# nrf54h20_enga_application register map
Vendor: Nordic Semiconductor; Series: nRF54h; File version: 1
CPU: CM33 r0p4, little endian, MPU, FPU, 3 interrupt priority bits, 480 interrupts, 4 SAU regions
Registers are 32-bit, read-write, reset 0x0 unless marked. A register's access mark holds for its fields unless they carry their own. Offsets are from the block's base; [hi:lo] are bit positions; lines under a group give offsets from that group; {n}, {i} and the like mark numbered series; 'fields as' and 'values as' point back to an identical list.

## GLOBAL_USBHSCORE0_NS (part 2 of 2) — USBHSCORE 0
Base 0x2F700000
Same registers: GLOBAL_USBHSCORE0_S 0x2F700000 (alternate view of GLOBAL_USBHSCORE0_NS)
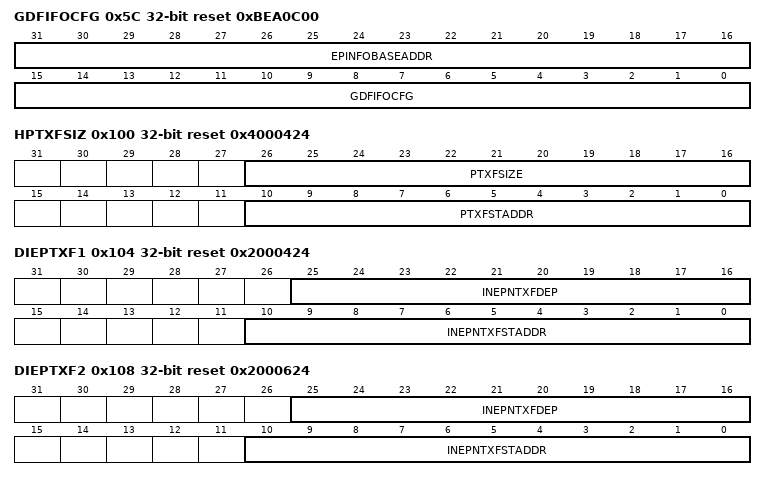
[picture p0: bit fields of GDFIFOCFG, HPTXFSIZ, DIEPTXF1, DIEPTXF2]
0x5C GDFIFOCFG reset 0xBEA0C00 — Global DFIFO Configuration Register
  [31:16] EPINFOBASEADDR, [15:0] GDFIFOCFG
0x68 GINTMSK2 — Interrupt Mask Register 2
0x6C GINTSTS2 — Interrupt Register 2
0x100 HPTXFSIZ reset 0x4000424 — Host Periodic Transmit FIFO Size Register
  [26:16] PTXFSIZE — Host Periodic TxFIFO Depth (PTxFSize)
  [10:0] PTXFSTADDR — Host Periodic TxFIFO Start Address (PTxFStAddr)
0x104 DIEPTXF1 reset 0x2000424 — Device IN Endpoint Transmit FIFO Size Register 1
  [25:16] INEPNTXFDEP — IN Endpoint TxFIFO Depth (INEPnTxFDep)
  [10:0] INEPNTXFSTADDR — IN Endpoint FIFOn Transmit RAM Start Address (INEPnTxFStAddr)
0x108 DIEPTXF2 reset 0x2000624 — Device IN Endpoint Transmit FIFO Size Register 2
  fields as DIEPTXF1
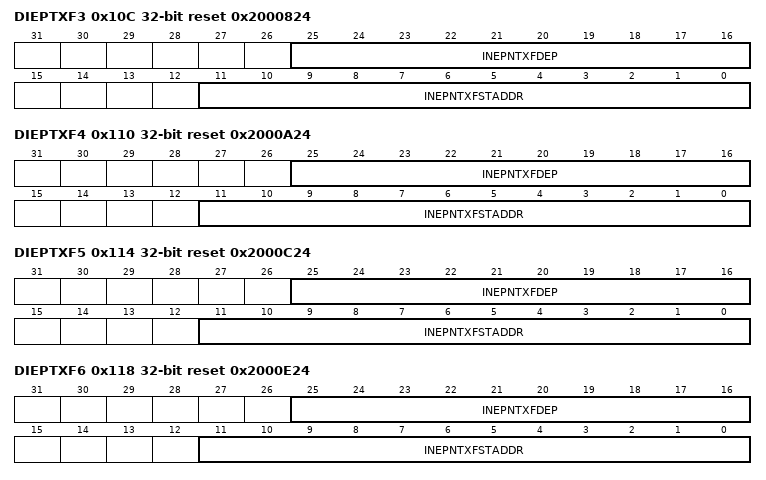
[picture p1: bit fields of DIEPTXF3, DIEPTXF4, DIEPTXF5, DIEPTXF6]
0x10C DIEPTXF3 reset 0x2000824 — Device IN Endpoint Transmit FIFO Size Register 3
  [25:16] INEPNTXFDEP — IN Endpoint TxFIFO Depth (INEPnTxFDep)
  [11:0] INEPNTXFSTADDR — IN Endpoint FIFOn Transmit RAM Start Address (INEPnTxFStAddr)
0x110 DIEPTXF4 reset 0x2000A24 — Device IN Endpoint Transmit FIFO Size Register 4
  fields as DIEPTXF3
0x114 DIEPTXF5 reset 0x2000C24 — Device IN Endpoint Transmit FIFO Size Register 5
  fields as DIEPTXF3
0x118 DIEPTXF6 reset 0x2000E24 — Device IN Endpoint Transmit FIFO Size Register 6
  fields as DIEPTXF3
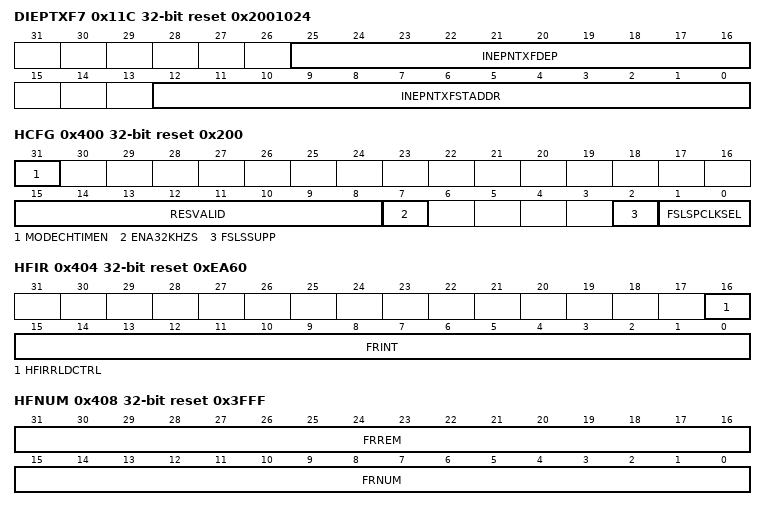
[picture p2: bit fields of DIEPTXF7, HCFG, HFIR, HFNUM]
0x11C DIEPTXF7 reset 0x2001024 — Device IN Endpoint Transmit FIFO Size Register 7
  [25:16] INEPNTXFDEP — IN Endpoint TxFIFO Depth (INEPnTxFDep)
  [12:0] INEPNTXFSTADDR — IN Endpoint FIFOn Transmit RAM Start Address (INEPnTxFStAddr)
0x400 HCFG reset 0x200 — Host Configuration Register
  [31] MODECHTIMEN — Mode Change Ready Timer Enable (ModeChTimEn)
    0=ENABLED (Unspecified); 1=DISABLED (Unspecified)
  [15:8] RESVALID — Resume Validation Period (ResValid)
  [7] ENA32KHZS — Enable 32 KHz Suspend mode (Ena32KHzS)
    0=DISABLED (Unspecified); 1=ENABLED (Unspecified)
  [2] FSLSSUPP — FS- and LS-Only Support (FSLSSupp)
    0=HSFSLS (Unspecified); 1=FSLS (Unspecified)
  [1:0] FSLSPCLKSEL — FS/LS PHY Clock Select (FSLSPclkSel)
    0=CLK3060 (Unspecified); 1=CLK48 (Unspecified); 2=CLK6 (Unspecified)
0x404 HFIR reset 0xEA60 — Host Frame Interval Register
  [16] HFIRRLDCTRL — Reload Control (HFIRRldCtrl)
    0=DISABLED (Unspecified); 1=ENABLED (Unspecified)
  [15:0] FRINT — Frame Interval (FrInt)
0x408 HFNUM reset 0x3FFF — Host Frame Number/Frame Time Remaining Register
  [31:16] FRREM ro — Frame Time Remaining (FrRem)
  [15:0] FRNUM ro — Frame Number (FrNum)
    0=INACTIVE (Unspecified); 1=ACTIVE (Unspecified)
0x414 HAINT — Host All Channels Interrupt Register
  [15:0] HAINT ro — Channel Interrupt for channel no.
    0=INACTIVE (Unspecified); 1=ACTIVE (Unspecified)
0x418 HAINTMSK — Host All Channels Interrupt Mask Register
  [15:0] HAINTMSK — Channel Interrupt Mask (HAINTMsk)
    0=UNMASK (Unspecified); 1=MASK (Unspecified)
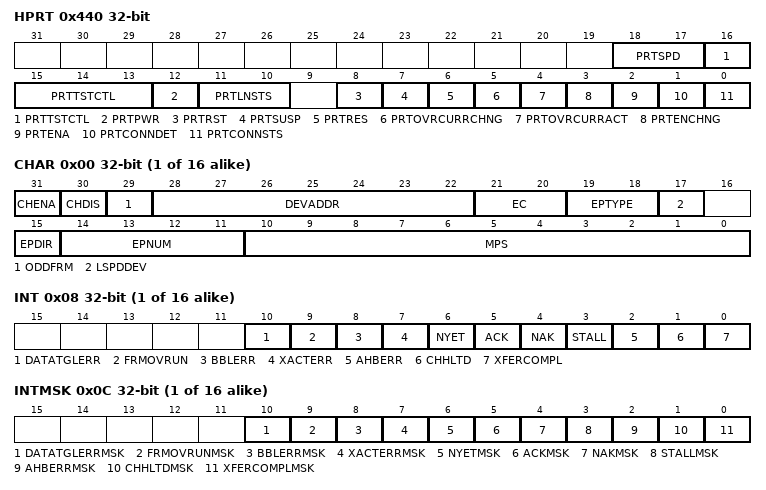
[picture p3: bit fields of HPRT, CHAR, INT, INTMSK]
0x440 HPRT — Host Port Control and Status Register
  [18:17] PRTSPD ro — Port Speed (PrtSpd)
    0=HIGHSPD (Unspecified); 1=FULLSPD (Unspecified); 2=LOWSPD (Unspecified)
  [16:13] PRTTSTCTL — Port Test Control (PrtTstCtl)
    0=DISABLED (Unspecified); 1=TESTJ (Unspecified); 2=TESTK (Unspecified); 3=TESTSN (Unspecified); 4=TESTPM (Unspecified); 5=TESTFENB (Unspecified)
  [12] PRTPWR — Port Power (PrtPwr)
    0=OFF (Unspecified); 1=ON (Unspecified)
  [11:10] PRTLNSTS ro — Port Line Status (PrtLnSts)
    1=PLUSD (Unspecified); 2=MINUSD (Unspecified)
  [8] PRTRST — Port Reset (PrtRst)
    0=DISABLED (Unspecified); 1=ENABLED (Unspecified)
  [7] PRTSUSP — Port Suspend (PrtSusp)
    0=INACTIVE (Unspecified); 1=ACTIVE (Unspecified)
  [6] PRTRES — Port Resume (PrtRes)
    0=NORESUME (Unspecified); 1=RESUME (Unspecified)
  [5] PRTOVRCURRCHNG — Port Overcurrent Change (PrtOvrCurrChng)
    0=INACTIVE (Unspecified); 1=ACTIVE (Unspecified)
  [4] PRTOVRCURRACT ro — Port Overcurrent Active (PrtOvrCurrAct)
    0=INACTIVE (Unspecified); 1=ACTIVE (Unspecified)
  [3] PRTENCHNG — Port Enable/Disable Change (PrtEnChng)
    0=INACTIVE (Unspecified); 1=ACTIVE (Unspecified)
  [2] PRTENA — Port Enable (PrtEna)
    0=DISABLED (Unspecified); 1=ENABLED (Unspecified)
  [1] PRTCONNDET — Port Connect Detected (PrtConnDet)
    0=INACTIVE (Unspecified); 1=ACTIVE (Unspecified)
  [0] PRTCONNSTS ro — Port Connect Status (PrtConnSts)
    0=NOTATTACHED (Unspecified); 1=ATTACHED (Unspecified)
{0x500+0x20*i} HC[{i}] (i=0..15) group — Unspecified
  0x00 CHAR — Description cluster: Host Channel n Characteristics Register
    [31] CHENA — Channel Enable (ChEna)
      0=DISABLED (Unspecified); 1=ENABLED (Unspecified)
    [30] CHDIS — Channel Disable (ChDis)
      0=INACTIVE (Unspecified); 1=ACTIVE (Unspecified)
    [29] ODDFRM — Odd Frame (OddFrm)
      0=EFRAME (Unspecified); 1=OFRAME (Unspecified)
    [28:22] DEVADDR — Device Address (DevAddr)
    [21:20] EC — Multi Count (MC) / Error Count (EC)
      1=TRANSONE (Unspecified); 2=TRANSTWO (Unspecified); 3=TRANSTHREE (Unspecified)
    [19:18] EPTYPE — Endpoint Type (EPType)
      0=CTRL (Unspecified); 1=ISOC (Unspecified); 2=BULK (Unspecified); 3=INTERR (Unspecified)
    [17] LSPDDEV — Low-Speed Device (LSpdDev)
      0=DISABLED (Unspecified); 1=ENABLED (Unspecified)
    [15] EPDIR — Endpoint Direction (EPDir)
      0=OUT (Unspecified); 1=IN (Unspecified)
    [14:11] EPNUM — Endpoint Number (EPNum)
      {v}=ENDPT{v} (Unspecified) (v=0..15)
    [10:0] MPS — Maximum Packet Size (MPS)
  0x08 INT — Description cluster: Host Channel n Interrupt Register
    [all] fields
      0=INACTIVE (Unspecified); 1=ACTIVE (Unspecified)
    [10] DATATGLERR — Data Toggle Error (DataTglErr).This bit can be set only by the core and the application should write 1 to clear
    [9] FRMOVRUN — Frame Overrun (FrmOvrun).
    [8] BBLERR — Babble Error (BblErr)
    [7] XACTERR — Transaction Error (XactErr)
    [6] NYET — NYET Response Received Interrupt (NYET)
    [5] ACK — ACK Response Received/Transmitted Interrupt (ACK)
    [4] NAK — NAK Response Received Interrupt (NAK)
    [3] STALL — STALL Response Received Interrupt (STALL)
    [2] AHBERR — AHB Error (AHBErr)
    [1] CHHLTD — Channel Halted (ChHltd)
    [0] XFERCOMPL — Transfer Completed (XferCompl)
  0x0C INTMSK — Description cluster: Host Channel n Interrupt Mask Register
    [all] fields
      0=MASK (Unspecified); 1=NOMASK (Unspecified)
    [10] DATATGLERRMSK — Data Toggle Error Mask (DataTglErrMsk)
    [9] FRMOVRUNMSK — Frame Overrun Mask (FrmOvrunMsk)
    [8] BBLERRMSK — Babble Error Mask (BblErrMsk)
    [7] XACTERRMSK — Transaction Error Mask (XactErrMsk)
    [6] NYETMSK — NYET Response Received Interrupt Mask (NyetMsk)
    [5] ACKMSK — ACK Response Received/Transmitted Interrupt Mask (AckMsk)
    [4] NAKMSK — NAK Response Received Interrupt Mask (NakMsk)
    [3] STALLMSK — STALL Response Received Interrupt Mask (StallMsk)
    [2] AHBERRMSK — AHB Error Mask (AHBErrMsk)
    [1] CHHLTDMSK — Channel Halted Mask (ChHltdMsk)
    [0] XFERCOMPLMSK — Transfer Completed Mask (XferComplMsk)
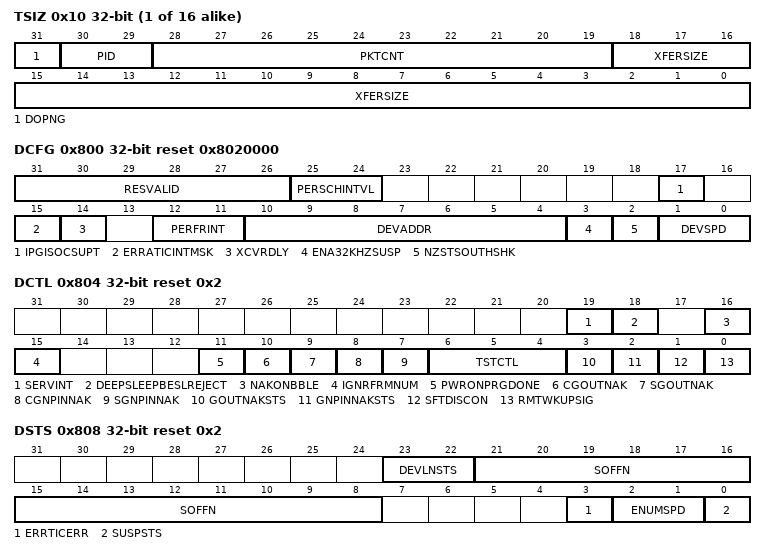
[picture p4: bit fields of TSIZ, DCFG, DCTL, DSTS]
  0x10 TSIZ — Description cluster: Host Channel n Transfer Size Register
    [31] DOPNG — Do Ping (DoPng)
      0=NOPING (Unspecified); 1=PING (Unspecified)
    [30:29] PID — PID (Pid)
      0=DATA0 (Unspecified); 1=DATA2 (Unspecified); 2=DATA1 (Unspecified); 3=MDATA (Unspecified)
    [28:19] PKTCNT — Packet Count (PktCnt)
    [18:0] XFERSIZE — Transfer Size (XferSize)
  0x14 DMA — Description cluster: Host Channel n DMA Address Register
    [31:0] DMAADDR — In Buffer DMA Mode:
0x800 DCFG reset 0x8020000 — Device Configuration Register
  [31:26] RESVALID — Resume Validation Period (ResValid)
  [25:24] PERSCHINTVL — Periodic Scheduling Interval (PerSchIntvl)
    0=MF25 (Unspecified); 1=MF50 (Unspecified); 2=MF75 (Unspecified)
  [17] IPGISOCSUPT — Worst-Case Inter-Packet Gap ISOC OUT Support (ipgisocSupt)
    0=DISABLED (Unspecified); 1=ENABLED (Unspecified)
  [15] ERRATICINTMSK — Erratic Error Interrupt Mask
    0=NOMASK (Unspecified); 1=MASK (Unspecified)
  [14] XCVRDLY
    0=DISABLE (Unspecified); 1=ENABLE (Unspecified)
  [12:11] PERFRINT — Periodic Frame Interval (PerFrInt)
    0=EOPF80 (Unspecified); 1=EOPF85 (Unspecified); 2=EOPF90 (Unspecified); 3=EOPF95 (Unspecified)
  [10:4] DEVADDR — Device Address (DevAddr)
  [3] ENA32KHZSUSP — Enable 32 KHz Suspend mode (Ena32KHzSusp)
    0=DISABLED (Unspecified); 1=ENABLED (Unspecified)
  [2] NZSTSOUTHSHK — Non-Zero-Length Status OUT Handshake (NZStsOUTHShk)
    0=SENDOUT (Unspecified); 1=SENDSTALL (Unspecified)
  [1:0] DEVSPD — Device Speed (DevSpd)
    0=USBHS20 (Unspecified); 1=USBFS20 (Unspecified); 2=USBLS116 (Unspecified); 3=USBFS1148 (Unspecified)
0x804 DCTL reset 0x2 — Device Control Register
  [19] SERVINT — Service Interval based scheduling for Isochronous IN Endpoints
    0=DISABLED (Unspecified); 1=ENABLED (Unspecified)
  [18] DEEPSLEEPBESLREJECT
    0=DISABLED (Unspecified); 1=ENABLED (Unspecified)
  [16] NAKONBBLE — NAK on Babble Error (NakOnBble)
    0=DISABLED (Unspecified); 1=ENABLED (Unspecified)
  [15] IGNRFRMNUM — Ignore Frame Number Feature for Isochronous Endpoints (IgnrFrmNum)
    0=DISABLED (Unspecified); 1=ENABLED (Unspecified)
  [11] PWRONPRGDONE — Power-On Programming Done (PWROnPrgDone)
    0=NOTDONE (Unspecified); 1=DONE (Unspecified)
  [10] CGOUTNAK wo — Clear Global OUT NAK (CGOUTNak)
    0=DISABLED (Unspecified); 1=ENABLED (Unspecified)
  [9] SGOUTNAK wo — Set Global OUT NAK (SGOUTNak)
    0=DISABLED (Unspecified); 1=ENABLED (Unspecified)
  [8] CGNPINNAK wo — Clear Global Non-periodic IN NAK (CGNPInNak)
    0=DISABLE (Unspecified); 1=ENABLE (Unspecified)
  [7] SGNPINNAK wo — Set Global Non-periodic IN NAK (SGNPInNak)
    0=DISABLE (Unspecified); 1=ENABLE (Unspecified)
  [6:4] TSTCTL — Test Control (TstCtl)
    0=DISABLED (Unspecified); 1=TESTJ (Unspecified); 2=TESTK (Unspecified); 3=TESTSN (Unspecified); 4=TESTPM (Unspecified); 5=TESTFE (Unspecified)
  [3] GOUTNAKSTS ro — Global OUT NAK Status (GOUTNakSts)
    0=INACTIVE (Unspecified); 1=ACTIVE (Unspecified)
  [2] GNPINNAKSTS ro — Global Non-periodic IN NAK Status (GNPINNakSts)
    0=INACTIVE (Unspecified); 1=ACTIVE (Unspecified)
  [1] SFTDISCON — Soft Disconnect (SftDiscon)
    0=NODISCONNECT (Unspecified); 1=DISCONNECT (Unspecified)
  [0] RMTWKUPSIG — Remote Wakeup Signaling (RmtWkUpSig)
    0=DISABLEDRMWKUP (Unspecified); 1=ENABLERMWKUP (Unspecified)
0x808 DSTS reset 0x2 — Device Status Register
  [23:22] DEVLNSTS ro — Device Line Status (DevLnSts)
  [21:8] SOFFN ro — Frame or Microframe Number of the Received SOF (SOFFN)
  [3] ERRTICERR ro — Erratic Error (ErrticErr)
    0=INACTIVE (Unspecified); 1=ACTIVE (Unspecified)
  [2:1] ENUMSPD ro — Enumerated Speed (EnumSpd)
    0=HS3060 (Unspecified); 1=FS3060 (Unspecified); 2=LS6 (Unspecified); 3=FS48 (Unspecified)
  [0] SUSPSTS ro — Suspend Status (SuspSts)
    0=INACTIVE (Unspecified); 1=ACTIVE (Unspecified)
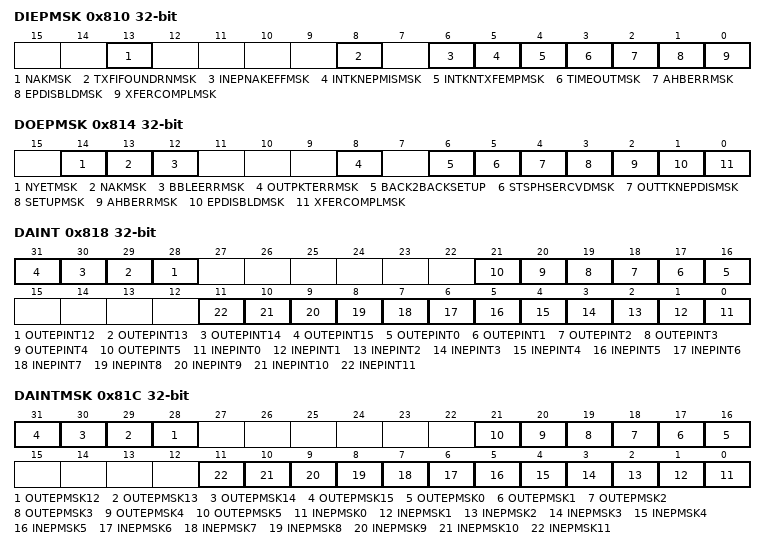
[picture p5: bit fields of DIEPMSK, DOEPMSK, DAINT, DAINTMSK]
0x810 DIEPMSK — Device IN Endpoint Common Interrupt Mask Register
  [all] fields
    0=MASK (Unspecified); 1=NOMASK (Unspecified)
  [13] NAKMSK — NAK interrupt Mask (NAKMsk)
  [8] TXFIFOUNDRNMSK — Fifo Underrun Mask (TxfifoUndrnMsk)
  [6] INEPNAKEFFMSK — IN Endpoint NAK Effective Mask (INEPNakEffMsk)
  [5] INTKNEPMISMSK — IN Token received with EP Mismatch Mask (INTknEPMisMsk)
  [4] INTKNTXFEMPMSK — IN Token Received When TxFIFO Empty Mask (INTknTXFEmpMsk)
  [3] TIMEOUTMSK — Timeout Condition Mask (TimeOUTMsk) (Non-isochronous endpoints)
  [2] AHBERRMSK — AHB Error Mask (AHBErrMsk)
  [1] EPDISBLDMSK — Endpoint Disabled Interrupt Mask (EPDisbldMsk)
  [0] XFERCOMPLMSK — Transfer Completed Interrupt Mask (XferComplMsk)
0x814 DOEPMSK — Device OUT Endpoint Common Interrupt Mask Register
  [all] fields
    0=MASK (Unspecified); 1=NOMASK (Unspecified)
  [14] NYETMSK — NYET interrupt Mask (NYETMsk)
  [13] NAKMSK — NAK interrupt Mask (NAKMsk)
  [12] BBLEERRMSK — Babble Error interrupt Mask (BbleErrMsk)
  [8] OUTPKTERRMSK — OUT Packet Error Mask (OutPktErrMsk)
  [6] BACK2BACKSETUP — Back-to-Back SETUP Packets Received Mask (Back2BackSETup)
  [5] STSPHSERCVDMSK — Status Phase Received Mask (StsPhseRcvdMsk)
  [4] OUTTKNEPDISMSK — OUT Token Received when Endpoint Disabled Mask (OUTTknEPdisMsk)
  [3] SETUPMSK — SETUP Phase Done Mask (SetUPMsk)
  [2] AHBERRMSK — AHB Error (AHBErrMsk)
  [1] EPDISBLDMSK — Endpoint Disabled Interrupt Mask (EPDisbldMsk)
  [0] XFERCOMPLMSK — Transfer Completed Interrupt Mask (XferComplMsk)
0x818 DAINT — Device All Endpoints Interrupt Register
  [all] fields
    0=INACTIVE (Unspecified); 1=ACTIVE (Unspecified)
  [n+16] OUTEPINT{n} ro (n=12..15) — OUT Endpoint {n} Interrupt Bit
  [n+16] OUTEPINT{n} ro (n=0..5) — OUT Endpoint {n} Interrupt Bit
  [n] INEPINT{n} ro (n=0..11) — IN Endpoint {n} Interrupt Bit
0x81C DAINTMSK — Device All Endpoints Interrupt Mask Register
  [all] fields
    0=MASK (Unspecified); 1=NOMASK (Unspecified)
  [n+16] OUTEPMSK{n} (n=12..15) — OUT Endpoint {n} Interrupt mask Bit
  [n+16] OUTEPMSK{n} (n=0..5) — OUT Endpoint {n} Interrupt mask Bit
  [n] INEPMSK{n} (n=0..11) — IN Endpoint {n} Interrupt mask Bit
0x828 DVBUSDIS reset 0x17D7 — Device VBUS Discharge Time Register
  [15:0] DVBUSDIS — Device VBUS Discharge Time (DVBUSDis)
0x82C DVBUSPULSE reset 0x5B8 — Device VBUS Pulsing Time Register
  [11:0] DVBUSPULSE — Device VBUS Pulsing Time (DVBUSPulse)
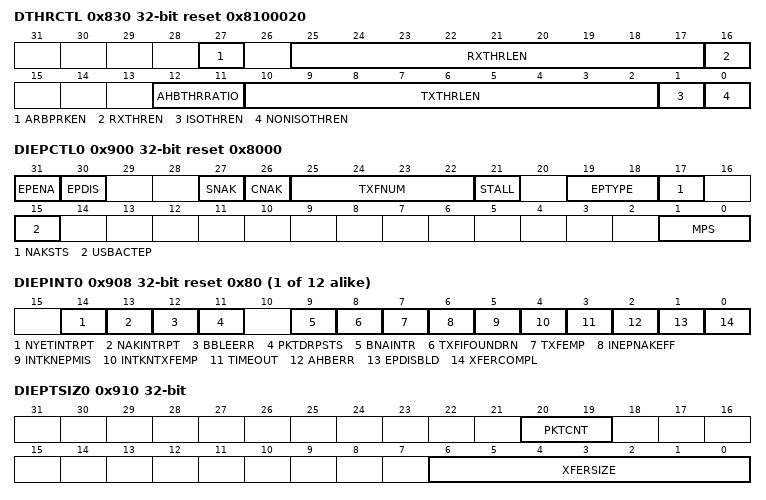
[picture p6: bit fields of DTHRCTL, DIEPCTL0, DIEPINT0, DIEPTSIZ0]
0x830 DTHRCTL reset 0x8100020 — Device Threshold Control Register
  [27] ARBPRKEN — Arbiter Parking Enable (ArbPrkEn)
    0=DISABLED (Unspecified); 1=ENABLED (Unspecified)
  [25:17] RXTHRLEN — Receive Threshold Length (RxThrLen)
  [16] RXTHREN — Receive Threshold Enable (RxThrEn)
    0=DISABLED (Unspecified); 1=ENABLED (Unspecified)
  [12:11] AHBTHRRATIO — AHB Threshold Ratio (AHBThrRatio)
    0=THRESZERO (Unspecified); 1=THRESONE (Unspecified); 2=THRESTWO (Unspecified); 3=THRESTHREE (Unspecified)
  [10:2] TXTHRLEN — Transmit Threshold Length (TxThrLen)
  [1] ISOTHREN — ISO IN Endpoints Threshold Enable. (ISOThrEn)
    0=DISABLED (Unspecified); 1=ENABLED (Unspecified)
  [0] NONISOTHREN — Non-ISO IN Endpoints Threshold Enable. (NonISOThrEn)
    0=DISABLED (Unspecified); 1=ENABLED (Unspecified)
0x834 DIEPEMPMSK — Device IN Endpoint FIFO Empty Interrupt Mask Register
  [15:0] INEPTXFEMPMSK — IN EP Tx FIFO Empty Interrupt Mask Bits (InEpTxfEmpMsk)
    1=EP0_MASK (Unspecified); 2=EP1_MASK (Unspecified); 4=EP2_MASK (Unspecified); 8=EP3_MASK (Unspecified); 16=EP4_MASK (Unspecified); 32=EP5_MASK (Unspecified); 64=EP6_MASK (Unspecified); 128=EP7_MASK (Unspecified); 0x100=EP8_MASK (Unspecified); 0x200=EP9_MASK (Unspecified); 0x400=EP10_MASK (Unspecified); 0x800=EP11_MASK (Unspecified); 0x1000=EP12_MASK (Unspecified); 0x2000=EP13_MASK (Unspecified); 0x4000=EP14_MASK (Unspecified); 0x8000=EP15_MASK (Unspecified)
0x900 DIEPCTL0 reset 0x8000 — Device Control IN Endpoint 0 Control Register
  [31] EPENA — Endpoint Enable (EPEna)
    0=INACTIVE (Unspecified); 1=ACTIVE (Unspecified)
  [30] EPDIS — Endpoint Disable (EPDis)
    0=INACTIVE (Unspecified); 1=ACTIVE (Unspecified)
  [27] SNAK wo — Set NAK (SNAK)
    0=NOSET (Unspecified); 1=SET (Unspecified)
  [26] CNAK wo — Clear NAK (CNAK)
    0=NOCLEAR (Unspecified); 1=CLEAR (Unspecified)
  [25:22] TXFNUM — TxFIFO Number (TxFNum)
    {v}=TXFIFO{v} (Unspecified) (v=0..15)
  [21] STALL — STALL Handshake (Stall)
    0=INACTIVE (Unspecified); 1=ACTIVE (Unspecified)
  [19:18] EPTYPE ro — Endpoint Type (EPType)
    0=ACTIVE (Unspecified)
  [17] NAKSTS ro — NAK Status (NAKSts)
    0=INACTIVE (Unspecified); 1=ACTIVE (Unspecified)
  [15] USBACTEP ro — USB Active Endpoint (USBActEP)
    1=ACTIVE0 (Unspecified)
  [1:0] MPS — Maximum Packet Size (MPS)
    0=BYTES64 (Unspecified); 1=BYTES32 (Unspecified); 2=BYTES16 (Unspecified); 3=BYTES8 (Unspecified)
{0x908+0x20*i} DIEPINT{i} reset 0x80 (i=0..11) — Device IN Endpoint {i} Interrupt Register
  [all] fields
    0=INACTIVE (Unspecified); 1=ACTIVE (Unspecified)
  [14] NYETINTRPT — NYET Interrupt (NYETIntrpt)
  [13] NAKINTRPT — NAK Interrupt (NAKInterrupt)
  [12] BBLEERR — NAK Interrupt (BbleErr)
  [11] PKTDRPSTS — Packet Drop Status (PktDrpSts)
  [9] BNAINTR — BNA (Buffer Not Available) Interrupt (BNAIntr)
  [8] TXFIFOUNDRN — Fifo Underrun (TxfifoUndrn)
  [7] TXFEMP ro — Transmit FIFO Empty (TxFEmp)
  [6] INEPNAKEFF — IN Endpoint NAK Effective (INEPNakEff)
  [5] INTKNEPMIS — IN Token Received with EP Mismatch (INTknEPMis)
  [4] INTKNTXFEMP — IN Token Received When TxFIFO is Empty (INTknTXFEmp)
  [3] TIMEOUT — Timeout Condition (TimeOUT)
  [2] AHBERR — AHB Error (AHBErr)
  [1] EPDISBLD — Endpoint Disabled Interrupt (EPDisbld)
  [0] XFERCOMPL — Transfer Completed Interrupt (XferCompl)
0x910 DIEPTSIZ0 — Device IN Endpoint 0 Transfer Size Register
  [20:19] PKTCNT — Packet Count (PktCnt)
  [6:0] XFERSIZE — Transfer Size (XferSize)
0x914 DIEPDMA0 — Device IN Endpoint 0 DMA Address Register
  [31:0] DMAADDR
0x918 DTXFSTS0 reset 0x200 — Device IN Endpoint Transmit FIFO Status Register 0
  [15:0] INEPTXFSPCAVAIL ro — IN Endpoint TxFIFO Space Avail (INEPTxFSpcAvail)
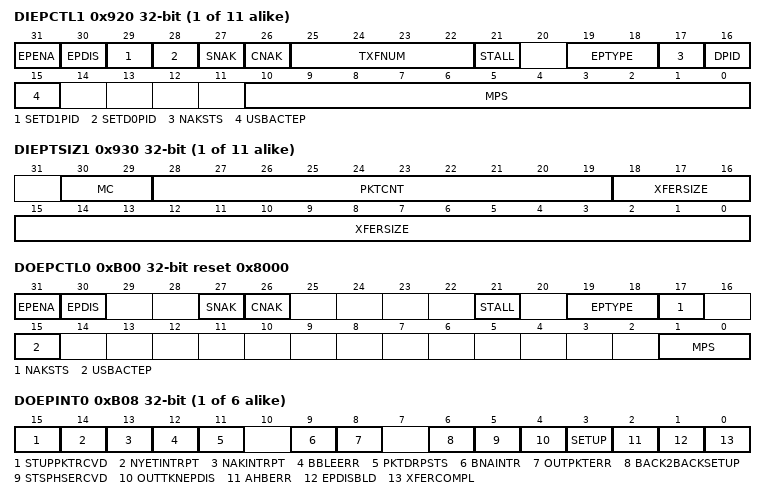
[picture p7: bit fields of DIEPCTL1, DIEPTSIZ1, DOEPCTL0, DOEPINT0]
{0x900+0x20*i} DIEPCTL{i} (i=1..11) — Device Control IN Endpoint {i} Control Register
  [31] EPENA — Endpoint Enable (EPEna)
    0=INACTIVE (Unspecified); 1=ACTIVE (Unspecified)
  [30] EPDIS — Endpoint Disable (EPDis)
    0=INACTIVE (Unspecified); 1=ACTIVE (Unspecified)
  [29] SETD1PID wo
    0=DISABLED (Unspecified); 1=ENABLED (Unspecified)
  [28] SETD0PID wo
    0=DISABLED (Unspecified); 1=ENABLED (Unspecified)
  [27] SNAK wo — Set NAK (SNAK)
    0=INACTIVE (Unspecified); 1=ACTIVE (Unspecified)
  [26] CNAK wo — Clear NAK (CNAK)
    0=INACTIVE (Unspecified); 1=ACTIVE (Unspecified)
  [25:22] TXFNUM — TxFIFO Number (TxFNum)
    {v}=TXFIFO{v} (Unspecified) (v=0..15)
  [21] STALL — STALL Handshake (Stall)
    0=INACTIVE (Unspecified); 1=ACTIVE (Unspecified)
  [19:18] EPTYPE — Endpoint Type (EPType)
    0=CONTROL (Unspecified); 1=ISOCHRONOUS (Unspecified); 2=BULK (Unspecified); 3=INTERRUP (Unspecified)
  [17] NAKSTS ro — NAK Status (NAKSts)
    0=NONNAK (Unspecified); 1=NAK (Unspecified)
  [16] DPID ro — Endpoint Data PID (DPID)
    0=DATA0EVENFRM (Unspecified); 1=DATA1ODDFRM (Unspecified)
  [15] USBACTEP — USB Active Endpoint (USBActEP)
    0=DISABLED (Unspecified); 1=ENABLED (Unspecified)
  [10:0] MPS — Maximum Packet Size (MPS)
{0x910+0x20*i} DIEPTSIZ{i} (i=1..11) — Device IN Endpoint {i} Transfer Size Register
  [30:29] MC
    1=PACKETONE (Unspecified); 2=PACKETTWO (Unspecified); 3=PACKETTHREE (Unspecified)
  [28:19] PKTCNT — Packet Count (PktCnt)
  [18:0] XFERSIZE — Transfer Size (XferSize)
{0x914+0x20*i} DIEPDMA{i} (i=1..11) — Device IN Endpoint {i} DMA Address Register
  [31:0] DMAADDR — Holds the start address of the external memory for storing or fetching endpoint
0x938 DTXFSTS1 reset 0x200 — This register reflects the status of the IN Endpoint Transmit FIFO Status Register 1 of the Device controller.
  fields as DTXFSTS0
{0x918+0x20*i} DTXFSTS{i} reset 0x200 (i=2..11) — Device IN Endpoint Transmit FIFO Status Register {i}
  fields as DTXFSTS0
0xB00 DOEPCTL0 reset 0x8000 — Device Control OUT Endpoint 0 Control Register
  [31] EPENA — Endpoint Enable (EPEna)
    0=INACTIVE (Unspecified); 1=ACTIVE (Unspecified)
  [30] EPDIS ro — Endpoint Disable (EPDis)
    0=INACTIVE (Unspecified)
  [27] SNAK wo — Set NAK (SNAK)
    0=NOSET (Unspecified); 1=SET (Unspecified)
  [26] CNAK wo — Clear NAK (CNAK)
    0=NOCLEAR (Unspecified); 1=CLEAR (Unspecified)
  [21] STALL — STALL Handshake (Stall)
    0=INACTIVE (Unspecified); 1=ACTIVE (Unspecified)
  [19:18] EPTYPE ro — Endpoint Type (EPType)
    0=ACTIVE (Unspecified)
  [17] NAKSTS ro — NAK Status (NAKSts)
    0=INACTIVE (Unspecified); 1=ACTIVE (Unspecified)
  [15] USBACTEP ro — USB Active Endpoint (USBActEP)
    1=ACTIVE (Unspecified)
  [1:0] MPS ro — Maximum Packet Size (MPS)
    0=BYTE64 (Unspecified); 1=BYTE32 (Unspecified); 2=BYTE16 (Unspecified); 3=BYTE8 (Unspecified)
{0xB08+0x20*i} DOEPINT{i} (i=0..5) — Device OUT Endpoint {i} Interrupt Register
  [15] STUPPKTRCVD — Setup Packet Received
    0=NOT_RCVD (Unspecified); 1=RCVD (Unspecified)
  [14] NYETINTRPT — NYET Interrupt (NYETIntrpt)
    0=INACTIVE (Unspecified); 1=ACTIVE (Unspecified)
  [13] NAKINTRPT — NAK Interrupt (NAKInterrupt)
    0=INACTIVE (Unspecified); 1=ACTIVE (Unspecified)
  [12] BBLEERR — NAK Interrupt (BbleErr)
    0=INACTIVE (Unspecified); 1=ACTIVE (Unspecified)
  [11] PKTDRPSTS — Packet Drop Status (PktDrpSts)
    0=INACTIVE (Unspecified); 1=ACTIVE (Unspecified)
  [9] BNAINTR — BNA (Buffer Not Available) Interrupt (BNAIntr)
    0=INACTIVE (Unspecified); 1=ACTIVE (Unspecified)
  [8] OUTPKTERR — OUT Packet Error (OutPktErr)
    0=INACTIVE (Unspecified); 1=ACTIVE (Unspecified)
  [6] BACK2BACKSETUP — Back-to-Back SETUP Packets Received (Back2BackSETup)
    0=INACTIVE (Unspecified); 1=ACTIVE (Unspecified)
  [5] STSPHSERCVD — Status Phase Received for Control Write (StsPhseRcvd)
    0=INACTIVE (Unspecified); 1=ACTIVE (Unspecified)
  [4] OUTTKNEPDIS — OUT Token Received When Endpoint Disabled (OUTTknEPdis)
    0=INACTIVE (Unspecified); 1=ACTIVE (Unspecified)
  [3] SETUP — SETUP Phase Done (SetUp)
    0=INACTIVE (Unspecified); 1=ACTIVE (Unspecified)
  [2] AHBERR — AHB Error (AHBErr)
    0=INACTIVE (Unspecified); 1=ACTIVE (Unspecified)
  [1] EPDISBLD — Endpoint Disabled Interrupt (EPDisbld)
    0=INACTIVE (Unspecified); 1=ACTIVE (Unspecified)
  [0] XFERCOMPL — Transfer Completed Interrupt (XferCompl)
    0=INACTIVE (Unspecified); 1=ACTIVE (Unspecified)
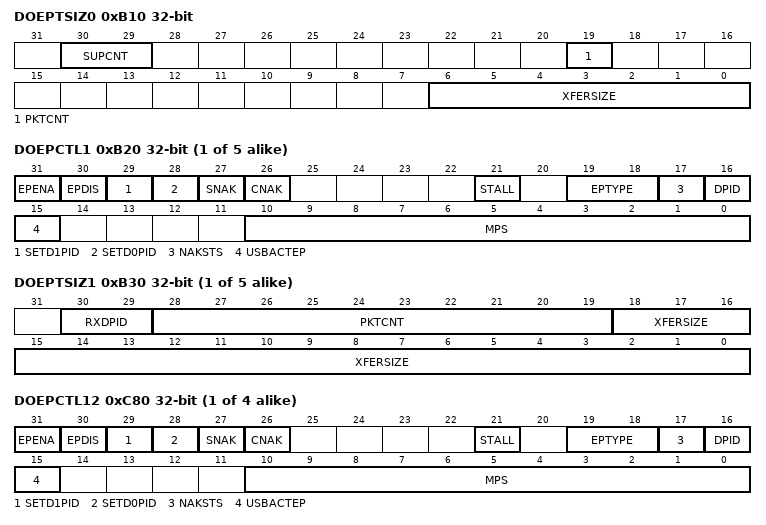
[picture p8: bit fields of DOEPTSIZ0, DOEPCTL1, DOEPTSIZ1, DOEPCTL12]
0xB10 DOEPTSIZ0 — Device OUT Endpoint 0 Transfer Size Register
  [30:29] SUPCNT — SETUP Packet Count (SUPCnt)
    1=ONEPACKET (Unspecified); 2=TWOPACKET (Unspecified); 3=THREEPACKET (Unspecified)
  [19] PKTCNT — Packet Count (PktCnt)
  [6:0] XFERSIZE — Transfer Size (XferSize)
{0xB14+0x20*i} DOEPDMA{i} (i=0..5) — Device OUT Endpoint {i} DMA Address Register
  fields as DIEPDMA1
{0xB00+0x20*i} DOEPCTL{i} (i=1..5) — Device Control OUT Endpoint {i} Control Register
  [31] EPENA — Endpoint Enable (EPEna)
    0=INACTIVE (Unspecified); 1=ACTIVE (Unspecified)
  [30] EPDIS — Endpoint Disable (EPDis)
    0=INACTIVE (Unspecified); 1=ACTIVE (Unspecified)
  [29] SETD1PID wo — Set DATA1 PID (SetD1PID)
    0=DISABLED (Unspecified); 1=ENABLED (Unspecified)
  [28] SETD0PID wo — Set DATA0 PID (SetD0PID)
    0=DISABLED (Unspecified); 1=ENABLED (Unspecified)
  [27] SNAK wo — Set NAK (SNAK)
    0=INACTIVE (Unspecified); 1=ACTIVE (Unspecified)
  [26] CNAK wo — Clear NAK (CNAK)
    0=INACTIVE (Unspecified); 1=ACTIVE (Unspecified)
  [21] STALL — STALL Handshake (Stall)
    0=INACTIVE (Unspecified); 1=ACTIVE (Unspecified)
  [19:18] EPTYPE — Endpoint Type (EPType)
    0=CONTROL (Unspecified); 1=ISOCHRONOUS (Unspecified); 2=BULK (Unspecified); 3=INTERRUPT (Unspecified)
  [17] NAKSTS ro — NAK Status (NAKSts)
    0=NONNAK (Unspecified); 1=NAK (Unspecified)
  [16] DPID ro — Endpoint Data PID (DPID)
    0=INACTIVE (Unspecified); 1=ACTIVE (Unspecified)
  [15] USBACTEP — USB Active Endpoint (USBActEP)
    0=DISABLED (Unspecified); 1=ENABLED (Unspecified)
  [10:0] MPS — Maximum Packet Size (MPS)
{0xB10+0x20*i} DOEPTSIZ{i} (i=1..5) — Device OUT Endpoint {i} Transfer Size Register
  [30:29] RXDPID ro
    0=DATA0 (Unspecified); 1=DATA2PACKET1 (Unspecified); 2=DATA1PACKET2 (Unspecified); 3=MDATAPACKET3 (Unspecified)
  [28:19] PKTCNT — Packet Count (PktCnt)
  [18:0] XFERSIZE — Transfer Size (XferSize)
{0xB00+0x20*i} DOEPCTL{i} (i=12..15) — Device Control OUT Endpoint {i} Control Register
  fields as DOEPCTL1
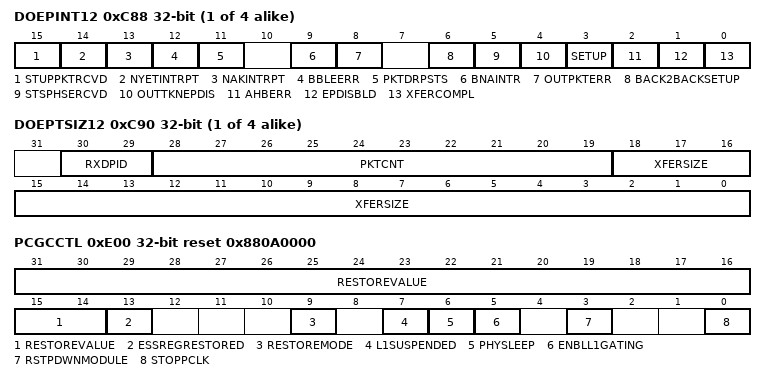
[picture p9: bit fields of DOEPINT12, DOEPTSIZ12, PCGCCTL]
{0xB08+0x20*i} DOEPINT{i} (i=12..15) — Device OUT Endpoint {i} Interrupt Register
  fields as DOEPINT0
{0xB10+0x20*i} DOEPTSIZ{i} (i=12..15) — Device OUT Endpoint {i} Transfer Size Register
  fields as DOEPTSIZ1
{0xB14+0x20*i} DOEPDMA{i} (i=12..15) — Device OUT Endpoint {i} DMA Address Register
  fields as DIEPDMA1
0xE00 PCGCCTL reset 0x880A0000 — Power and Clock Gating Control Register
  [31:14] RESTOREVALUE — Restore Value (RestoreValue)
  [13] ESSREGRESTORED wo — Essential Register Values Restored (EssRegRestored)
    0=NOT_RESTORED (Unspecified); 1=RESTORED (Unspecified)
  [9] RESTOREMODE — Restore Mode (RestoreMode)
    0=DISABLED (Unspecified); 1=ENABLED (Unspecified)
  [7] L1SUSPENDED ro — L1 Deep Sleep
    0=INACTIVE (Unspecified); 1=ACTIVE (Unspecified)
  [6] PHYSLEEP ro — PHY In Sleep
    0=INACTIVE (Unspecified); 1=ACTIVE (Unspecified)
  [5] ENBLL1GATING — Enable Sleep Clock Gating
    0=DISABLED (Unspecified); 1=ENABLED (Unspecified)
  [3] RSTPDWNMODULE — Reset Power-Down Modules (RstPdwnModule)
    0=ON (Unspecified); 1=OFF (Unspecified)
  [0] STOPPCLK — Stop Pclk (StopPclk)
    0=DISABLED (Unspecified); 1=ENABLED (Unspecified)
{0x1000+0x1004*i} DWCOTGDFIFO[{i}] (i=0..15) group — Unspecified
  {0x0+4j} DATA[{j}] (j=0..1024) — Description collection: Data buffer for FIFO n
0x20000 DWCOTGDFIFODIRECTACCESS group — Unspecified
  {0x0+4j} DATA[{j}] (j=0..4096) — Description collection: Data buffer FIFO Direct Access
